# Arty register map
Vendor: Xilinx; Series: 100T
C-Class CPU Core, 64-bit RV64IMAC core
CPU: C-Class, little endian
Registers are 32-bit, read-write, reset 0x0 unless marked. A register's access mark holds for its fields unless they carry their own. Offsets are from the block's base; lines under a group give offsets from that group; [hi:lo] are bit positions; {n}, {i} and the like mark numbered series; 'fields as' and 'values as' point back to an identical list; <NAME> marks a mode.

## Memory map
0x02100000 SHAKTI_GPIO size 0x1000 — General purpose input/output controller.

## Interrupts
{n+8} GPIO_{n}_IRQ (SHAKTI_GPIO) (n=0..31)

## SHAKTI_GPIO — General purpose input/output controller.
Base 0x02100000
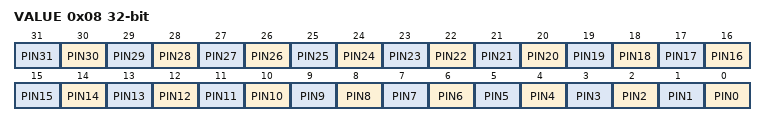
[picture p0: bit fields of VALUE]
0x08 VALUE — Pin value.
  [n] PIN{n} (n=0..31)
